# ESP32S31_RADIO register map
Vendor: Espressif; Series: ESP32-S31; File version: 3.52
Registers are 32-bit, read-write, no defined reset value unless marked. A register's access mark holds for its fields unless they carry their own. Offsets are from the block's base; [hi:lo] are bit positions; {n}, {i} and the like mark numbered series; 'fields as' and 'values as' point back to an identical list.

## WIFI_MAC_BLOCK_ACK — Block-ack registers of the Wi-Fi MAC beside the RX descriptor walker, at the same base: the per-queue TX block-ack state, the RX block-ack agreement update and the extra soft-AP RX block-ack entry.
Base 0x20104000
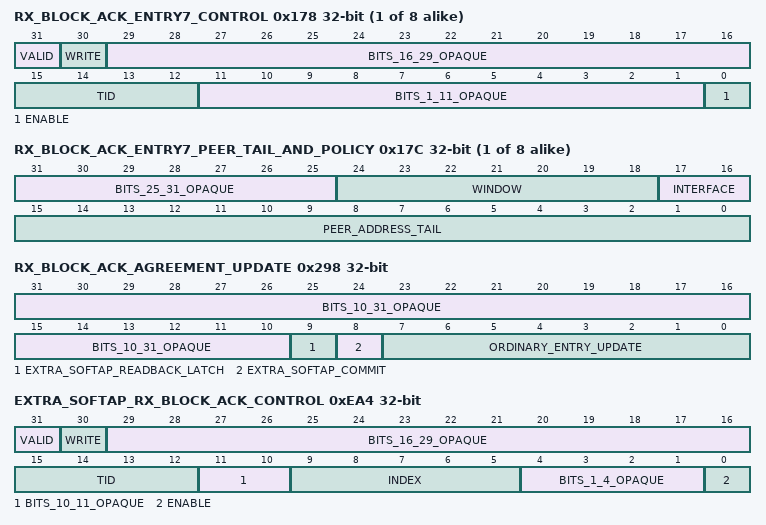
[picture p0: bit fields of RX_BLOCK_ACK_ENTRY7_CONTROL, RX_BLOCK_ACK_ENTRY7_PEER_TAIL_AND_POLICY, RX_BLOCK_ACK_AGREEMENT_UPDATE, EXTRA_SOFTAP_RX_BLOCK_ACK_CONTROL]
0x178 RX_BLOCK_ACK_ENTRY{x}_CONTROL (x=7,6,5,4,3,2,1,0; step 0x24) — Project-assigned name. Configuration word in one of eight reverse-addressed ordinary receive BlockAck banks. Physical array index zero is logical hardware index seven; complete hal_agreement_add_rx_ba writes logical index zero at 0x20104274 and subtracts 0x24 per index. Delete clears VALID, clears both load bitmaps, sets VALID once, then clears this complete word.
  [31] VALID — Project-assigned name. Marks an installed entry. Complete delete clears and reasserts it around bitmap clearing before zeroing the entry.
  [30] WRITE — Project-assigned name. Complete add sets this bit together with ENABLE and VALID when publishing the entry configuration.
  [29:16] BITS_16_29_OPAQUE — Opaque: meaning not established. Bits preserved by reads but cleared by every reviewed zero-based ordinary-entry publication.
  [15:12] TID — Project-assigned name. Traffic identifier passed to complete hal_agreement_add_rx_ba without the extra staging path's index transform. The field is four bits wide, while complete ht_recv_action_ba_addba_request rejects values with bit three set and therefore admits TIDs zero through seven.
  [11:1] BITS_1_11_OPAQUE — Opaque: meaning not established. Bits preserved by reads but cleared by every reviewed zero-based ordinary-entry publication.
  [0] ENABLE — Project-assigned name. Complete add sets this bit in every installed ordinary receive BlockAck entry.
0x17C RX_BLOCK_ACK_ENTRY{x}_PEER_TAIL_AND_POLICY (x=7,6,5,4,3,2,1,0; step 0x24) — Project-assigned name. Peer MAC bytes four and five, interface number and receive reorder-window size in one reverse-addressed ordinary receive BlockAck bank. Complete vendor ampdu_rx_start limits the protocol agreement by the peer request and configured receive window; its ordinary hardware-activation branch independently passes the constant 64 to ic_add_rx_ba. Complete hal_agreement_add_rx_ba then stores that value in WINDOW.
  [31:25] BITS_25_31_OPAQUE — Opaque: meaning not established. Bits cleared by every reviewed zero-based ordinary-entry policy publication.
  [24:18] WINDOW — Project-assigned name. Seven-bit hardware receive BlockAck window. The normal vendor ordinary-STA activation path publishes 64.
  [17:16] INTERFACE — Project-assigned name.
  [15:0] PEER_ADDRESS_TAIL — Project-assigned name.
0x180 RX_BLOCK_ACK_ENTRY{x}_PEER_HEAD (x=7,6,5,4,3,2,1,0; step 0x24) — Project-assigned name. Peer MAC bytes zero through three in little-endian order in one reverse-addressed ordinary receive BlockAck bank.
  [31:0] PEER_ADDRESS_HEAD — Project-assigned name.
0x184 RX_BLOCK_ACK_ENTRY{x}_CURRENT_SEQUENCE (x=7,6,5,4,3,2,1,0; step 0x24) ro — Project-assigned name. Hardware-maintained twelve-bit receive/reorder sequence state. Complete libpp[hal_ampdu.o]::hal_ba_session_store snapshots this word and complete libpp[hal_ampdu.o]::hal_ba_session_restore copies its saved low twelve bits into START_SEQUENCE_LOAD.
  [11:0] SEQUENCE — Project-assigned name.
0x188 RX_BLOCK_ACK_ENTRY{x}_START_SEQUENCE_LOAD (x=7,6,5,4,3,2,1,0; step 0x24) — Project-assigned name. Twelve-bit starting sequence written by complete add/reset/restore leaves. This is the software load word paired with the adjacent hardware-maintained CURRENT_SEQUENCE word.
  [11:0] SEQUENCE — Project-assigned name.
0x18C RX_BLOCK_ACK_ENTRY{x}_BITMAP_LOW_STATUS (x=7,6,5,4,3,2,1,0; step 0x24) ro — Project-assigned name. Hardware-maintained low reorder bitmap. Complete libpp[hal_ampdu.o]::hal_ba_session_store snapshots this word and restore copies it into BITMAP_LOW_LOAD while VALID is clear.
  [31:0] BITMAP — Project-assigned name. Low 32 bits of the hardware-maintained receive reorder bitmap.
0x190 RX_BLOCK_ACK_ENTRY{x}_BITMAP_LOW_LOAD (x=7,6,5,4,3,2,1,0; step 0x24) — Project-assigned name. Software load word for the low reorder bitmap. Complete add and delete clear it; complete session restore writes the saved low status bitmap here while VALID is clear.
  [31:0] BITMAP — Project-assigned name. Low 32 bits of the software-loaded receive reorder bitmap.
0x194 RX_BLOCK_ACK_ENTRY{x}_BITMAP_HIGH_STATUS (x=7,6,5,4,3,2,1,0; step 0x24) ro — Project-assigned name. Hardware-maintained high reorder bitmap. Complete libpp[hal_ampdu.o]::hal_ba_session_store snapshots this word and restore copies it into BITMAP_HIGH_LOAD while VALID is clear.
  [31:0] BITMAP — Project-assigned name. High 32 bits of the hardware-maintained receive reorder bitmap.
0x198 RX_BLOCK_ACK_ENTRY{x}_BITMAP_HIGH_LOAD (x=7,6,5,4,3,2,1,0; step 0x24) — Project-assigned name. Software load word for the high reorder bitmap. Complete add and delete clear it; complete session restore writes the saved high status bitmap here while VALID is clear.
  [31:0] BITMAP — Project-assigned name. High 32 bits of the software-loaded receive reorder bitmap.
0x298 RX_BLOCK_ACK_AGREEMENT_UPDATE — Project-assigned name. Ordinary add/reset sets one of bits zero through seven for the corresponding direct bank. The independent extra-SoftAP staging path pulses bit eight to commit and uses bit nine to latch a selected entry for readback.
  [31:10] BITS_10_31_OPAQUE — Opaque: meaning not established. Observed source use; the individual hardware meaning is unknown.
  [9] EXTRA_SOFTAP_READBACK_LATCH — Project-assigned name. Complete extra-SoftAP diagnostics, reset and delete set this bit while reading the entry selected in the staging control and clear it afterwards.
  [8] EXTRA_SOFTAP_COMMIT — Project-assigned name. Complete extra-SoftAP add/reset/delete pulses this bit high then low after filling the shared staging words.
  [7:0] ORDINARY_ENTRY_UPDATE — Project-assigned name. One update bit per reverse-addressed ordinary receive BlockAck bank. Complete add/reset performs a fresh-read OR with one shifted by the logical hardware index.
0xEA4 EXTRA_SOFTAP_RX_BLOCK_ACK_CONTROL — Project-assigned name. Shared staging and readback-control word used only by complete hal_agreement_*_extra_softap_rx_ba leaves. Ordinary STA/AP receive BlockAck agreements use the eight direct banks at 0x20104178..0x20104294 instead.
  [31] VALID — Project-assigned name.
  [30] WRITE — Project-assigned name.
  [29:16] BITS_16_29_OPAQUE — Opaque: meaning not established. Bits cleared by every reviewed zero-based extra-SoftAP control publication.
  [15:12] TID — Project-assigned name.
  [11:10] BITS_10_11_OPAQUE — Opaque: meaning not established. Bits cleared by every reviewed zero-based extra-SoftAP control publication.
  [9:5] INDEX — Project-assigned name.
  [4:1] BITS_1_4_OPAQUE — Opaque: meaning not established. The pinned full-word diagnostic output consumes these lanes; individual hardware meanings remain unknown.
  [0] ENABLE — Project-assigned name.
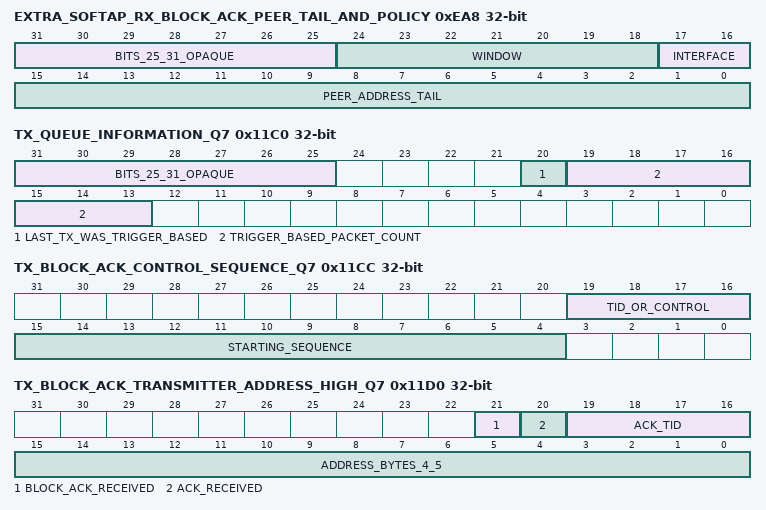
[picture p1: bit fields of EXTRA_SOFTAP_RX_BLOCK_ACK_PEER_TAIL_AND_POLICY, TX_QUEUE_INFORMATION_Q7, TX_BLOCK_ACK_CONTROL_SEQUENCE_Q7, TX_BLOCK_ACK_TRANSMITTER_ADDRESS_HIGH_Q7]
0xEA8 EXTRA_SOFTAP_RX_BLOCK_ACK_PEER_TAIL_AND_POLICY — Project-assigned name. Shared extra-SoftAP staging word carrying peer MAC bytes four and five, interface and reorder-window size.
  [31:25] BITS_25_31_OPAQUE — Opaque: meaning not established. The pinned full-word diagnostic output consumes these lanes; individual hardware meanings remain unknown.
  [24:18] WINDOW — Project-assigned name.
  [17:16] INTERFACE — Project-assigned name.
  [15:0] PEER_ADDRESS_TAIL — Project-assigned name.
0xEAC EXTRA_SOFTAP_RX_BLOCK_ACK_PEER_HEAD — Project-assigned name. Shared extra-SoftAP staging word carrying peer MAC bytes zero through three in little-endian order.
  [31:0] PEER_ADDRESS_HEAD — Project-assigned name. Peer MAC address bytes zero through three in little-endian order.
0xEB0 EXTRA_SOFTAP_RX_BLOCK_ACK_START_SEQUENCE — Project-assigned name. Shared extra-SoftAP staging word carrying the twelve-bit starting sequence.
  [11:0] SEQUENCE — Project-assigned name.
0xEB4 EXTRA_SOFTAP_RX_BLOCK_ACK_BITMAP_LOW — Project-assigned name. Shared extra-SoftAP low receive/reorder bitmap staging word, cleared when installing or removing an entry.
  [31:0] BITMAP — Project-assigned name. Low 32 bits of the selected extra-SoftAP receive reorder bitmap.
0xEB8 EXTRA_SOFTAP_RX_BLOCK_ACK_BITMAP_HIGH — Project-assigned name. Shared extra-SoftAP high receive/reorder bitmap staging word, cleared when installing or removing an entry.
  [31:0] BITMAP — Project-assigned name. High 32 bits of the selected extra-SoftAP receive reorder bitmap.
0x11C0 TX_QUEUE_INFORMATION_Q7 ro — Project-assigned name. WDEVTXQ_TXINFO for reverse-addressed hardware queue 7.
  [31:25] BITS_25_31_OPAQUE — Opaque: meaning not established. Observed source use; the individual hardware meaning is unknown.
  [20] LAST_TX_WAS_TRIGGER_BASED — Project-assigned name.
  [19:13] TRIGGER_BASED_PACKET_COUNT — Project-assigned name.
0x11C4 TX_BLOCK_ACK_BITMAP_HIGH_Q7 ro — Project-assigned name. WDEVTXQBA_BMHI for reverse-addressed hardware queue 7.
  [31:0] BITMAP — Project-assigned name.
0x11C8 TX_BLOCK_ACK_BITMAP_LOW_Q7 ro — Project-assigned name. WDEVTXQBA_BMLO for reverse-addressed hardware queue 7.
  [31:0] BITMAP — Project-assigned name.
0x11CC TX_BLOCK_ACK_CONTROL_SEQUENCE_Q7 ro — Project-assigned name. WDEVTXQBA_SSN: starting sequence bits 15:4 and TID/control bits 19:16 for queue 7.
  [19:16] TID_OR_CONTROL — Project-assigned name.
  [15:4] STARTING_SEQUENCE — Project-assigned name.
0x11D0 TX_BLOCK_ACK_TRANSMITTER_ADDRESS_HIGH_Q7 ro — Project-assigned name. WDEVTXQBA_TAHI; the blob identifies the low sixteen bits as the high two transmitter-address bytes and the upper fields as ACK/BlockAck result state.
  [21] BLOCK_ACK_RECEIVED — Project-assigned name.
  [20] ACK_RECEIVED — Project-assigned name.
  [19:16] ACK_TID — Project-assigned name.
  [15:0] ADDRESS_BYTES_4_5 — Project-assigned name.
0x11D4 TX_BLOCK_ACK_TRANSMITTER_ADDRESS_LOW_Q7 ro — Project-assigned name. WDEVTXQBA_TALO; low four transmitter-address bytes.
  [31:0] ADDRESS_BYTES_0_3 — Project-assigned name.
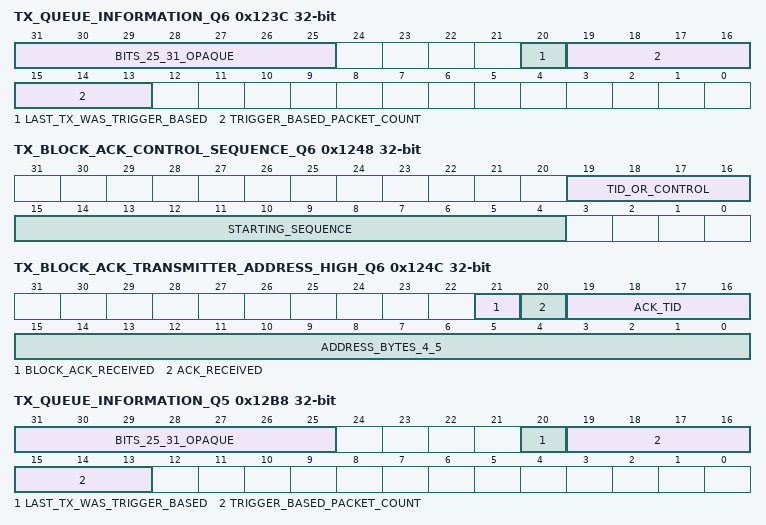
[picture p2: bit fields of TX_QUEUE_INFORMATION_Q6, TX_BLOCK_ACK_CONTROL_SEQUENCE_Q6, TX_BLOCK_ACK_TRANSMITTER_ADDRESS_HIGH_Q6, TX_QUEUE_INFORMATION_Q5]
0x123C TX_QUEUE_INFORMATION_Q6 ro — Project-assigned name. WDEVTXQ_TXINFO for reverse-addressed hardware queue 6.
  fields as TX_QUEUE_INFORMATION_Q7
0x1240 TX_BLOCK_ACK_BITMAP_HIGH_Q6 ro — Project-assigned name. WDEVTXQBA_BMHI for reverse-addressed hardware queue 6.
  [31:0] BITMAP — Project-assigned name.
0x1244 TX_BLOCK_ACK_BITMAP_LOW_Q6 ro — Project-assigned name. WDEVTXQBA_BMLO for reverse-addressed hardware queue 6.
  [31:0] BITMAP — Project-assigned name.
0x1248 TX_BLOCK_ACK_CONTROL_SEQUENCE_Q6 ro — Project-assigned name. WDEVTXQBA_SSN: starting sequence bits 15:4 and TID/control bits 19:16 for queue 6.
  fields as TX_BLOCK_ACK_CONTROL_SEQUENCE_Q7
0x124C TX_BLOCK_ACK_TRANSMITTER_ADDRESS_HIGH_Q6 ro — Project-assigned name. WDEVTXQBA_TAHI; the blob identifies the low sixteen bits as the high two transmitter-address bytes and the upper fields as ACK/BlockAck result state.
  fields as TX_BLOCK_ACK_TRANSMITTER_ADDRESS_HIGH_Q7
0x1250 TX_BLOCK_ACK_TRANSMITTER_ADDRESS_LOW_Q6 ro — Project-assigned name. WDEVTXQBA_TALO; low four transmitter-address bytes.
  [31:0] ADDRESS_BYTES_0_3 — Project-assigned name.
0x12B8 TX_QUEUE_INFORMATION_Q5 ro — Project-assigned name. WDEVTXQ_TXINFO for reverse-addressed hardware queue 5.
  fields as TX_QUEUE_INFORMATION_Q7
0x12BC TX_BLOCK_ACK_BITMAP_HIGH_Q5 ro — Project-assigned name. WDEVTXQBA_BMHI for reverse-addressed hardware queue 5.
  [31:0] BITMAP — Project-assigned name.
0x12C0 TX_BLOCK_ACK_BITMAP_LOW_Q5 ro — Project-assigned name. WDEVTXQBA_BMLO for reverse-addressed hardware queue 5.
  [31:0] BITMAP — Project-assigned name.
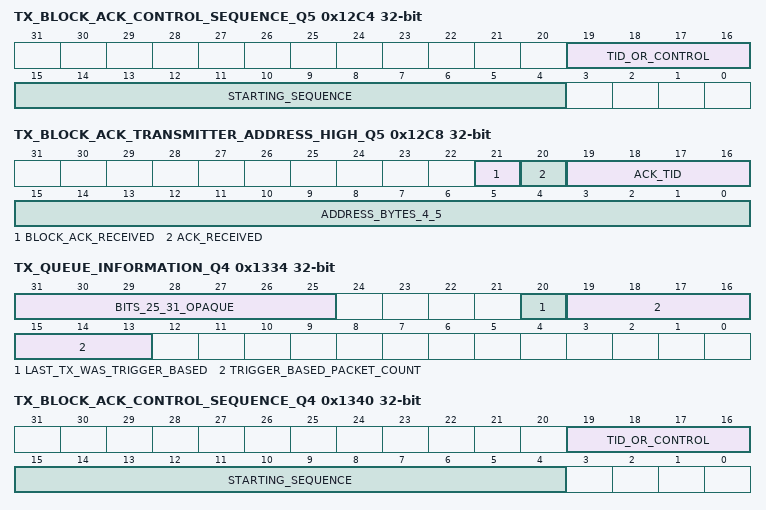
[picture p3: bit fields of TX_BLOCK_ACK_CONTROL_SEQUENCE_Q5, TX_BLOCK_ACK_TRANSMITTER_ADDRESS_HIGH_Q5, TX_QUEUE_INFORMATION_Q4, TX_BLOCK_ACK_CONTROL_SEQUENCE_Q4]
0x12C4 TX_BLOCK_ACK_CONTROL_SEQUENCE_Q5 ro — Project-assigned name. WDEVTXQBA_SSN: starting sequence bits 15:4 and TID/control bits 19:16 for queue 5.
  fields as TX_BLOCK_ACK_CONTROL_SEQUENCE_Q7
0x12C8 TX_BLOCK_ACK_TRANSMITTER_ADDRESS_HIGH_Q5 ro — Project-assigned name. WDEVTXQBA_TAHI; the blob identifies the low sixteen bits as the high two transmitter-address bytes and the upper fields as ACK/BlockAck result state.
  fields as TX_BLOCK_ACK_TRANSMITTER_ADDRESS_HIGH_Q7
0x12CC TX_BLOCK_ACK_TRANSMITTER_ADDRESS_LOW_Q5 ro — Project-assigned name. WDEVTXQBA_TALO; low four transmitter-address bytes.
  [31:0] ADDRESS_BYTES_0_3 — Project-assigned name.
0x1334 TX_QUEUE_INFORMATION_Q4 ro — Project-assigned name. WDEVTXQ_TXINFO for reverse-addressed hardware queue 4.
  fields as TX_QUEUE_INFORMATION_Q7
0x1338 TX_BLOCK_ACK_BITMAP_HIGH_Q4 ro — Project-assigned name. WDEVTXQBA_BMHI for reverse-addressed hardware queue 4.
  [31:0] BITMAP — Project-assigned name.
0x133C TX_BLOCK_ACK_BITMAP_LOW_Q4 ro — Project-assigned name. WDEVTXQBA_BMLO for reverse-addressed hardware queue 4.
  [31:0] BITMAP — Project-assigned name.
0x1340 TX_BLOCK_ACK_CONTROL_SEQUENCE_Q4 ro — Project-assigned name. WDEVTXQBA_SSN: starting sequence bits 15:4 and TID/control bits 19:16 for queue 4.
  fields as TX_BLOCK_ACK_CONTROL_SEQUENCE_Q7
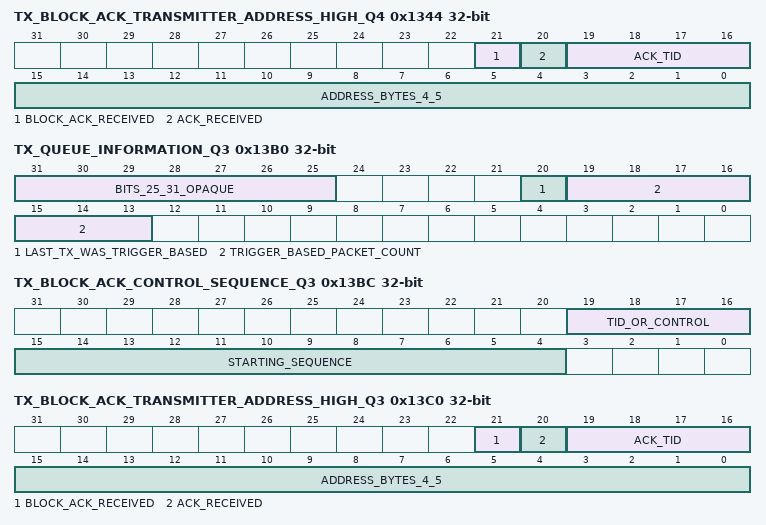
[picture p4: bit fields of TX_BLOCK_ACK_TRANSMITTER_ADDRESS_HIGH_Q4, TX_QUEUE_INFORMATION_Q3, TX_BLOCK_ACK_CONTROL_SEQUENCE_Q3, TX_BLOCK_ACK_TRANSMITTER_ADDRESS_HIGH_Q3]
0x1344 TX_BLOCK_ACK_TRANSMITTER_ADDRESS_HIGH_Q4 ro — Project-assigned name. WDEVTXQBA_TAHI; the blob identifies the low sixteen bits as the high two transmitter-address bytes and the upper fields as ACK/BlockAck result state.
  fields as TX_BLOCK_ACK_TRANSMITTER_ADDRESS_HIGH_Q7
0x1348 TX_BLOCK_ACK_TRANSMITTER_ADDRESS_LOW_Q4 ro — Project-assigned name. WDEVTXQBA_TALO; low four transmitter-address bytes.
  [31:0] ADDRESS_BYTES_0_3 — Project-assigned name.
0x13B0 TX_QUEUE_INFORMATION_Q3 ro — Project-assigned name. WDEVTXQ_TXINFO for reverse-addressed hardware queue 3.
  fields as TX_QUEUE_INFORMATION_Q7
0x13B4 TX_BLOCK_ACK_BITMAP_HIGH_Q3 ro — Project-assigned name. High 32 acknowledgement bits for completed hardware queue 3.
  [31:0] BITMAP — Project-assigned name.
0x13B8 TX_BLOCK_ACK_BITMAP_LOW_Q3 ro — Project-assigned name. Low 32 acknowledgement bits for completed hardware queue 3.
  [31:0] BITMAP — Project-assigned name.
0x13BC TX_BLOCK_ACK_CONTROL_SEQUENCE_Q3 ro — Project-assigned name. Control bits 19:16 and starting sequence bits 15:4 for completed hardware queue 3.
  fields as TX_BLOCK_ACK_CONTROL_SEQUENCE_Q7
0x13C0 TX_BLOCK_ACK_TRANSMITTER_ADDRESS_HIGH_Q3 ro — Project-assigned name. WDEVTXQBA_TAHI; high two transmitter-address bytes plus ACK/BlockAck result state.
  fields as TX_BLOCK_ACK_TRANSMITTER_ADDRESS_HIGH_Q7
0x13C4 TX_BLOCK_ACK_TRANSMITTER_ADDRESS_LOW_Q3 ro — Project-assigned name. WDEVTXQBA_TALO; low four transmitter-address bytes.
  [31:0] ADDRESS_BYTES_0_3 — Project-assigned name.
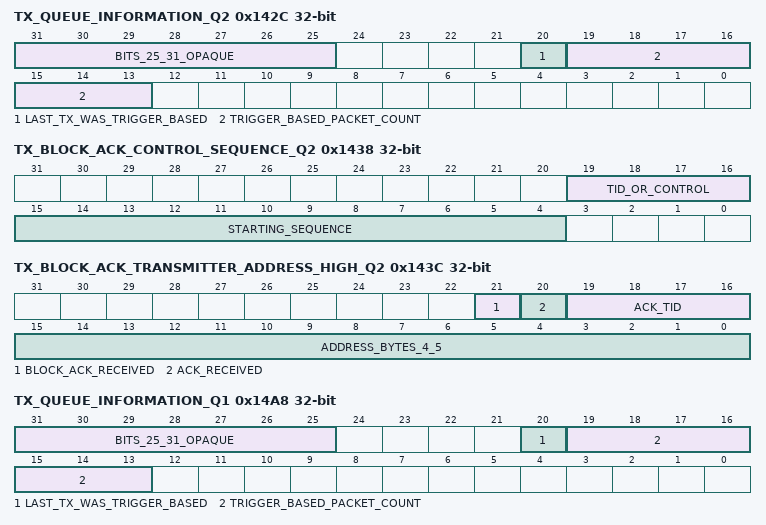
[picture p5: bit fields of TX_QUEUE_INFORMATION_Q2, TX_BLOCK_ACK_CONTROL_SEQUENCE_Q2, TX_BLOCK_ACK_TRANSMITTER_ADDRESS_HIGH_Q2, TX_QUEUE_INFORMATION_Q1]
0x142C TX_QUEUE_INFORMATION_Q2 ro — Project-assigned name. WDEVTXQ_TXINFO for reverse-addressed hardware queue 2.
  fields as TX_QUEUE_INFORMATION_Q7
0x1430 TX_BLOCK_ACK_BITMAP_HIGH_Q2 ro — Project-assigned name. High 32 acknowledgement bits for completed hardware queue 2.
  [31:0] BITMAP — Project-assigned name.
0x1434 TX_BLOCK_ACK_BITMAP_LOW_Q2 ro — Project-assigned name. Low 32 acknowledgement bits for completed hardware queue 2.
  [31:0] BITMAP — Project-assigned name.
0x1438 TX_BLOCK_ACK_CONTROL_SEQUENCE_Q2 ro — Project-assigned name. Control bits 19:16 and starting sequence bits 15:4 for completed hardware queue 2.
  fields as TX_BLOCK_ACK_CONTROL_SEQUENCE_Q7
0x143C TX_BLOCK_ACK_TRANSMITTER_ADDRESS_HIGH_Q2 ro — Project-assigned name. WDEVTXQBA_TAHI; high two transmitter-address bytes plus ACK/BlockAck result state.
  fields as TX_BLOCK_ACK_TRANSMITTER_ADDRESS_HIGH_Q7
0x1440 TX_BLOCK_ACK_TRANSMITTER_ADDRESS_LOW_Q2 ro — Project-assigned name. WDEVTXQBA_TALO; low four transmitter-address bytes.
  [31:0] ADDRESS_BYTES_0_3 — Project-assigned name.
0x14A8 TX_QUEUE_INFORMATION_Q1 ro — Project-assigned name. WDEVTXQ_TXINFO for reverse-addressed hardware queue 1.
  fields as TX_QUEUE_INFORMATION_Q7
0x14AC TX_BLOCK_ACK_BITMAP_HIGH_Q1 ro — Project-assigned name. High 32 acknowledgement bits for completed hardware queue 1.
  [31:0] BITMAP — Project-assigned name.
0x14B0 TX_BLOCK_ACK_BITMAP_LOW_Q1 ro — Project-assigned name. Low 32 acknowledgement bits for completed hardware queue 1.
  [31:0] BITMAP — Project-assigned name.
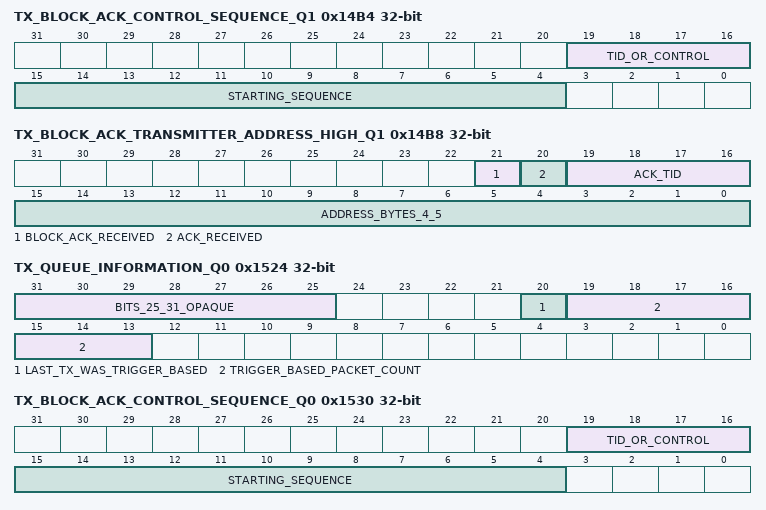
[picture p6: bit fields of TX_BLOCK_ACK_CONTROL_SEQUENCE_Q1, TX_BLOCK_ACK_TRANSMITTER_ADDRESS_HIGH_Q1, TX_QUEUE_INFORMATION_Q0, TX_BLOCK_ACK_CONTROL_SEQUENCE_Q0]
0x14B4 TX_BLOCK_ACK_CONTROL_SEQUENCE_Q1 ro — Project-assigned name. Control bits 19:16 and starting sequence bits 15:4 for completed hardware queue 1.
  fields as TX_BLOCK_ACK_CONTROL_SEQUENCE_Q7
0x14B8 TX_BLOCK_ACK_TRANSMITTER_ADDRESS_HIGH_Q1 ro — Project-assigned name. WDEVTXQBA_TAHI; high two transmitter-address bytes plus ACK/BlockAck result state.
  fields as TX_BLOCK_ACK_TRANSMITTER_ADDRESS_HIGH_Q7
0x14BC TX_BLOCK_ACK_TRANSMITTER_ADDRESS_LOW_Q1 ro — Project-assigned name. WDEVTXQBA_TALO; low four transmitter-address bytes.
  [31:0] ADDRESS_BYTES_0_3 — Project-assigned name.
0x1524 TX_QUEUE_INFORMATION_Q0 ro — Project-assigned name. WDEVTXQ_TXINFO for reverse-addressed hardware queue 0.
  fields as TX_QUEUE_INFORMATION_Q7
0x1528 TX_BLOCK_ACK_BITMAP_HIGH_Q0 ro — Project-assigned name. High 32 acknowledgement bits for completed hardware queue 0, sampled before acknowledging the completion edge.
  [31:0] BITMAP — Project-assigned name.
0x152C TX_BLOCK_ACK_BITMAP_LOW_Q0 ro — Project-assigned name. Low 32 acknowledgement bits for completed hardware queue 0, sampled before acknowledging the completion edge.
  [31:0] BITMAP — Project-assigned name.
0x1530 TX_BLOCK_ACK_CONTROL_SEQUENCE_Q0 ro — Project-assigned name. Control bits 19:16 and starting sequence bits 15:4 for completed hardware queue 0, sampled before acknowledging the completion edge.
  fields as TX_BLOCK_ACK_CONTROL_SEQUENCE_Q7
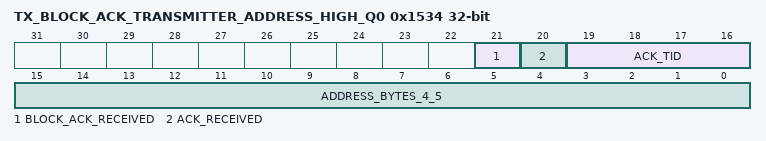
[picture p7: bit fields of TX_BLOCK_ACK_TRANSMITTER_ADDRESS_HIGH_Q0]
0x1534 TX_BLOCK_ACK_TRANSMITTER_ADDRESS_HIGH_Q0 ro — Project-assigned name. WDEVTXQBA_TAHI; high two transmitter-address bytes plus ACK/BlockAck result state for completed queue 0.
  fields as TX_BLOCK_ACK_TRANSMITTER_ADDRESS_HIGH_Q7
0x1538 TX_BLOCK_ACK_TRANSMITTER_ADDRESS_LOW_Q0 ro — Project-assigned name. WDEVTXQBA_TALO; low four transmitter-address bytes for completed queue 0.
  [31:0] ADDRESS_BYTES_0_3 — Project-assigned name.
